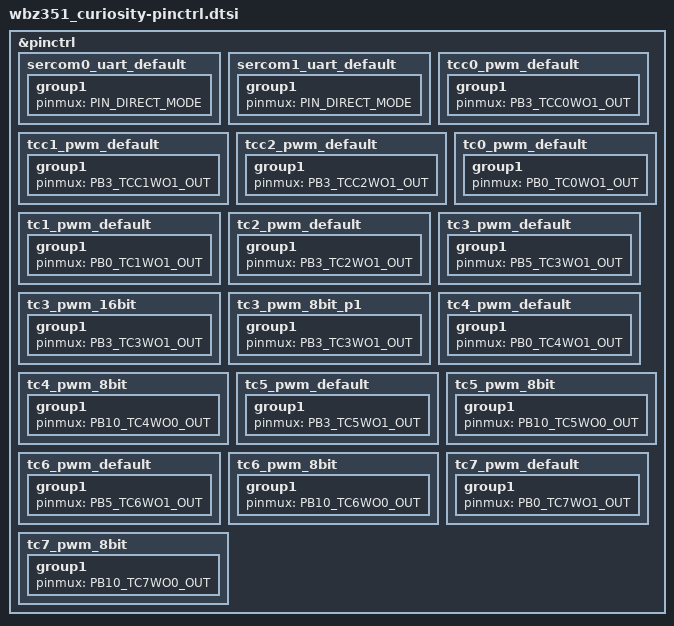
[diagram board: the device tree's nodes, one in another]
/*
 * Copyright (c) 2025 Microchip Technology Inc.
 *
 * SPDX-License-Identifier: Apache-2.0
 */

#include <dt-bindings/pic32c/pic32cx_bz/bz3/pic32cx5109bz31048-pinctrl.h>

&pinctrl {
	sercom0_uart_default: sercom0_uart_default {
		group1 {
			pinmux = <PIN_DIRECT_MODE>;
		};
	};

	sercom1_uart_default: sercom1_uart_default {
		group1 {
			pinmux = <PIN_DIRECT_MODE>;
		};
	};

	tcc0_pwm_default: tcc0_pwm_default {
		group1 {
			pinmux = <PB3_TCC0WO1_OUT>;
		};
	};

	tcc1_pwm_default: tcc1_pwm_default {
		group1 {
			pinmux = <PB3_TCC1WO1_OUT>;
		};
	};

	tcc2_pwm_default: tcc2_pwm_default {
		group1 {
			pinmux = <PB3_TCC2WO1_OUT>;
		};
	};

	tc0_pwm_default: tc0_pwm_default {
		group1 {
			pinmux = <PB0_TC0WO1_OUT>;
		};
	};

	tc1_pwm_default: tc1_pwm_default {
		group1 {
			pinmux = <PB0_TC1WO1_OUT>;
		};
	};

	tc2_pwm_default: tc2_pwm_default {
		group1 {
			pinmux = <PB3_TC2WO1_OUT>;
		};
	};

	tc3_pwm_default: tc3_pwm_default {
		group1 {
			pinmux = <PB5_TC3WO1_OUT>;
		};
	};


	tc3_pwm_16bit: tc3_pwm_16bit {
		group1 {
			pinmux = <PB3_TC3WO1_OUT>;
		};
	};

	tc3_pwm_8bit_p1: tc3_pwm_8bit_p1 {
		group1 {
			pinmux = <PB3_TC3WO1_OUT>;
		};
	};

	tc4_pwm_default: tc4_pwm_default {
		group1 {
			pinmux = <PB0_TC4WO1_OUT>;
		};
	};

	tc4_pwm_8bit: tc4_pwm_8bit {
		group1 {
			pinmux = <PB10_TC4WO0_OUT>;
		};
	};

	tc5_pwm_default: tc5_pwm_default {
		group1 {
			pinmux = <PB3_TC5WO1_OUT>;
		};
	};

	tc5_pwm_8bit: tc5_pwm_8bit {
		group1 {
			pinmux = <PB10_TC5WO0_OUT>;
		};
	};

	tc6_pwm_default: tc6_pwm_default {
		group1 {
			pinmux = <PB5_TC6WO1_OUT>;
		};
	};

	tc6_pwm_8bit: tc6_pwm_8bit {
		group1 {
			pinmux = <PB10_TC6WO0_OUT>;
		};
	};

	tc7_pwm_default: tc7_pwm_default {
		group1 {
			pinmux = <PB0_TC7WO1_OUT>;
		};
	};

	tc7_pwm_8bit: tc7_pwm_8bit {
		group1 {
			pinmux = <PB10_TC7WO0_OUT>;
		};
	};

};
